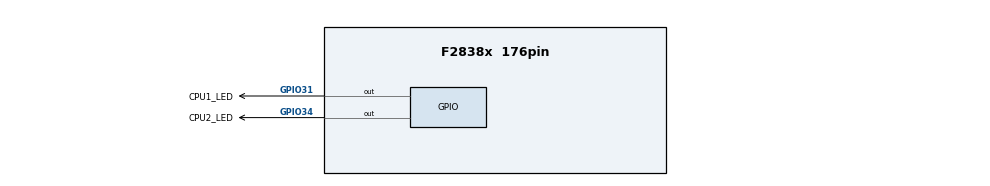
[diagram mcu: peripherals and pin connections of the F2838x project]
/**
 * @cliArgs --device "F2838x" --package "176pin" --part "F2838x_176pin" --context "CPU1" --product "C2000WARE@5.02.00.00"
 * @versions {"tool":"1.17.0+3128"}
 */

/**
 * Import the modules used in this configuration.
 */
const adc    = scripting.addModule("/driverlib/adc.js", {}, false);
const adc1   = adc.addInstance();
const cla    = scripting.addModule("/driverlib/cla.js", {}, false);
const cla1   = cla.addInstance();
const gpio   = scripting.addModule("/driverlib/gpio.js", {}, false);
const gpio1  = gpio.addInstance();
const gpio2  = gpio.addInstance();
const ipc    = scripting.addModule("/driverlib/ipc.js");
const memcfg = scripting.addModule("/driverlib/memcfg.js");

/**
 * Write custom configuration values to the imported modules.
 */
adc1.adcClockPrescaler       = "ADC_CLK_DIV_4_0";
adc1.enabledSOCs             = ["ADC_SOC_NUMBER0"];
adc1.soc0Trigger             = "ADC_TRIGGER_EPWM1_SOCA";
adc1.soc0SampleWindow        = 64;
adc1.interruptPulseMode      = "ADC_PULSE_END_OF_CONV";
adc1.enabledInts             = ["ADC_INT_NUMBER1"];
adc1.enableInterrupt1        = true;
adc1.registerInterrupts      = ["1"];
adc1.$name                   = "CPU1_ADCA";
adc1.adcInt1.enableInterrupt = true;

cla1.$name              = "myCLA0";
cla1.cpuint_CLA_TASK_1  = false;
cla1.cpuint_CLA_TASK_2  = false;
cla1.cpuint_CLA_TASK_3  = false;
cla1.cpuint_CLA_TASK_4  = false;
cla1.cpuint_CLA_TASK_5  = false;
cla1.cpuint_CLA_TASK_6  = false;
cla1.cpuint_CLA_TASK_7  = false;
cla1.cpuint_CLA_TASK_8  = false;
cla1.enable_CLA_TASK_2  = false;
cla1.enable_CLA_TASK_3  = false;
cla1.enable_CLA_TASK_4  = false;
cla1.enable_CLA_TASK_5  = false;
cla1.enable_CLA_TASK_6  = false;
cla1.enable_CLA_TASK_7  = false;
cla1.enable_CLA_TASK_8  = false;
cla1.trigger_CLA_TASK_1 = "CLA_TRIGGER_ADCA1";

gpio1.direction       = "GPIO_DIR_MODE_OUT";
gpio1.$name           = "CPU1_LED";
gpio1.gpioPin.$assign = "GPIO31";

gpio2.direction       = "GPIO_DIR_MODE_OUT";
gpio2.controllerCore  = "GPIO_CORE_CPU2";
gpio2.$name           = "CPU2_LED";
gpio2.gpioPin.$assign = "GPIO34";

ipc.ipcRegisterFlag = ["IPC_FLAG31"];
ipc.flagHandler31   = "IPC_SYNC";

memcfg.config_MEMCFG_SECT_LS5        = "CLA_prog";
memcfg.config_MEMCFG_SECT_LS0        = "CLA_data";
memcfg.config_MEMCFG_SECT_LS1        = "CLA_data";
memcfg.init_MEMCFG_SECT_MSGCPUTOCLA1 = true;
memcfg.init_MEMCFG_SECT_MSGCLA1TOCPU = true;
